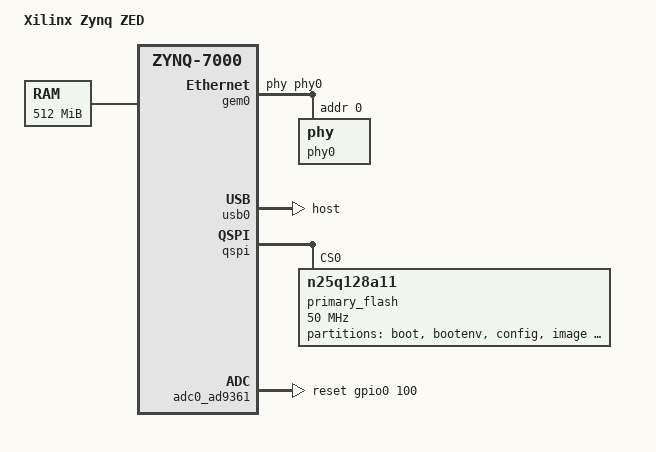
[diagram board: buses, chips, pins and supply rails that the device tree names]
/*
 * CAUTION: This file is automatically generated by Xilinx.
 * Version:  
 * Today is: Tue Jan 23 23:09:45 2024
 */


/dts-v1/;
#include "zynq-7000.dtsi"
#include "pl.dtsi"
#include "pcw.dtsi"

/ {
	model = "Xilinx Zynq ZED";
	chosen {
		bootargs = "console=ttyPS0,115200 root=/dev/mmcblk0p2 rw earlyprintk rootfstype=ext4 rootwait";
		stdout-path = "/amba@0/uart@E0001000";
	};

	aliases {
		ethernet0 = &gem0;
		serial0 = &uart1;
		i2c0 = &fmc_iic;
		spi0 = &qspi;
		spi1 = &spi0;
		spi2 = &spi1;
	};

	memory {
		device_type = "memory";
		reg = <0x000000000 0x20000000>;
	};
};

&gem0 {
	phy0: phy@0 {
		device_type = "ethernet-phy";
		reg = <0x0>;
		marvell,reg-init=<3 16 0xff00 0x1e 3 17 0xfff0 0x0a>;
	};
	phy-handle = <&phy0>;
};

&usb0 {
	xlnx,phy-reset-gpio = <&gpio0 85 0>;
	dr_mode = "host"; /* This breaks OTG mode */
};

&qspi {
	primary_flash: ps7-qspi@0 {
		#address-cells = <1>;
		#size-cells = <1>;
		compatible = "n25q128a11";
		reg = <0x0>;
		spi-max-frequency = <50000000>;
		partition@0 {
			label = "boot";
			reg = <0x00000000 0x00500000>;
		};
		partition@500000 {
			label = "bootenv";
			reg = <0x00500000 0x00020000>;
		};
		partition@520000 {
			label = "config";
			reg = <0x00520000 0x00020000>;
		};
		partition@540000 {
			label = "image";
			reg = <0x00540000 0x00a80000>;
		};
		partition@fc0000 {
			label = "spare";
			reg = <0x00fc0000 0x00000000>;
		};
	};
};

#define fmc_spi spi0
#include "adi-fmcomms2.dtsi"

/* fixup */
&adc0_ad9361 {
	en_agc-gpios = <&gpio0 98 0>;
	sync-gpios = <&gpio0 99 0>;
	reset-gpios = <&gpio0 100 0>;
	enable-gpios = <&gpio0 101 0>;
	txnrx-gpios = <&gpio0 102 0>;
};

